# TM4C129ENCPDT register map
File version: 1.0
CPU: CORTEX_M4 1.0, other endian, MPU, FPU, 3 interrupt priority bits
Registers are 32-bit, read-write, reset 0x0 unless marked. A register's access mark holds for its fields unless they carry their own. Offsets are from the block's base; [hi:lo] are bit positions; {n}, {i} and the like mark numbered series.

## ADC0 — ADC register offsets
Base 0x40038000
Same registers: ADC1 0x40039000
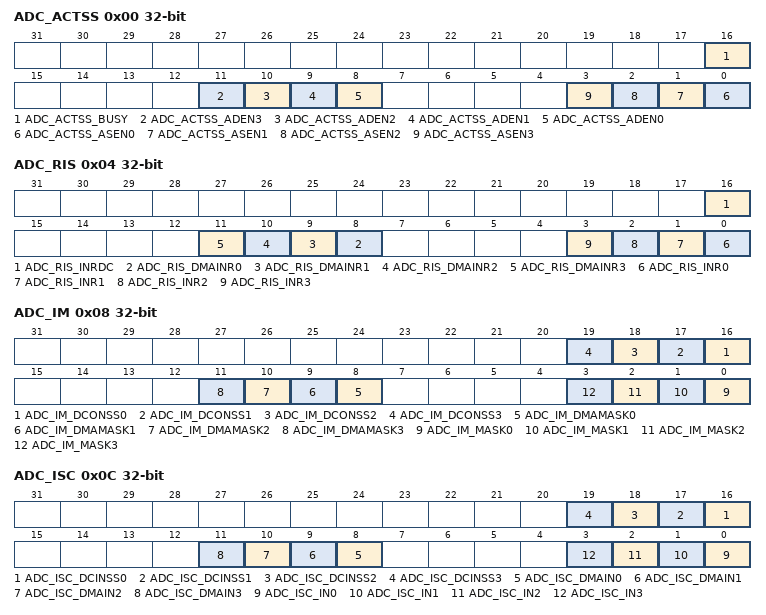
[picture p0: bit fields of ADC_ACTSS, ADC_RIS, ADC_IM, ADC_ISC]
0x00 ADC_ACTSS — ADC Active Sample Sequencer
  [16] ADC_ACTSS_BUSY — [16:16] ADC Busy
  [11] ADC_ACTSS_ADEN3 — [11:11] ADC SS3 DMA Enable
  [10] ADC_ACTSS_ADEN2 — [10:10] ADC SS2 DMA Enable
  [9] ADC_ACTSS_ADEN1 — [9:9] ADC SS1 DMA Enable
  [8] ADC_ACTSS_ADEN0 — [8:8] ADC SS1 DMA Enable
  [n] ADC_ACTSS_ASEN{n} (n=0..3) — [{n}:{n}] ADC SS{n} Enable
0x04 ADC_RIS — ADC Raw Interrupt Status
  [16] ADC_RIS_INRDC — [16:16] Digital Comparator Raw Interrupt Status
  [n+8] ADC_RIS_DMAINR{n} (n=0..3) — [{n+8}:{n+8}] SS{n} DMA Raw Interrupt Status
  [n] ADC_RIS_INR{n} (n=0..3) — [{n}:{n}] SS{n} Raw Interrupt Status
0x08 ADC_IM — ADC Interrupt Mask
  [n+16] ADC_IM_DCONSS{n} (n=0..3) — [{n+16}:{n+16}] Digital Comparator Interrupt on SS{n}
  [n+8] ADC_IM_DMAMASK{n} (n=0..3) — [{n+8}:{n+8}] SS{n} DMA Interrupt Mask
  [n] ADC_IM_MASK{n} (n=0..3) — [{n}:{n}] SS{n} Interrupt Mask
0x0C ADC_ISC — ADC Interrupt Status and Clear
  [n+16] ADC_ISC_DCINSS{n} (n=0..3) — [{n+16}:{n+16}] Digital Comparator Interrupt Status on SS{n}
  [n+8] ADC_ISC_DMAIN{n} (n=0..3) — [{n+8}:{n+8}] SS{n} DMA Interrupt Status and Clear
  [n] ADC_ISC_IN{n} (n=0..3) — [{n}:{n}] SS{n} Interrupt Status and Clear
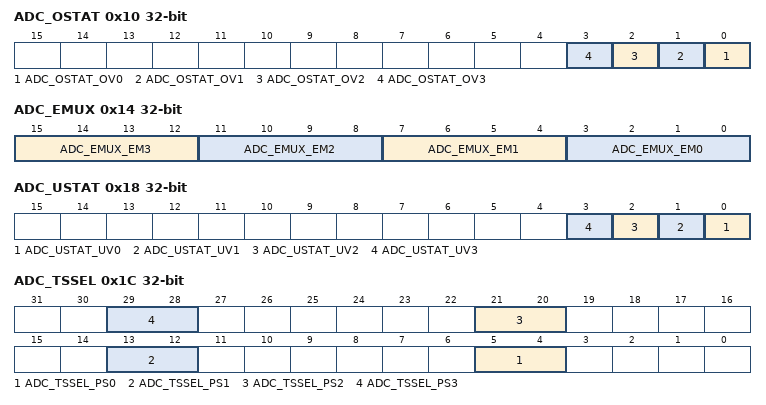
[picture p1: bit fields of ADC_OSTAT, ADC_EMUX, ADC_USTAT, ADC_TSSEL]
0x10 ADC_OSTAT — ADC Overflow Status
  [n] ADC_OSTAT_OV{n} (n=0..3) — [{n}:{n}] SS{n} FIFO Overflow
0x14 ADC_EMUX — ADC Event Multiplexer Select
  [15:12] ADC_EMUX_EM3 — [15:12] SS3 Trigger Select
    0=ADC_EMUX_EM3_PROCESSOR (Processor (default)); 0x1000=ADC_EMUX_EM3_COMP0 (Analog Comparator 0); 0x2000=ADC_EMUX_EM3_COMP1 (Analog Comparator 1); 0x3000=ADC_EMUX_EM3_COMP2 (Analog Comparator 2); 0x4000=ADC_EMUX_EM3_EXTERNAL (External (GPIO Pins)); 0x5000=ADC_EMUX_EM3_TIMER (Timer); 0x6000=ADC_EMUX_EM3_PWM0 (PWM generator 0); 0x7000=ADC_EMUX_EM3_PWM1 (PWM generator 1); 0x8000=ADC_EMUX_EM3_PWM2 (PWM generator 2); 0x9000=ADC_EMUX_EM3_PWM3 (PWM generator 3); 0xE000=ADC_EMUX_EM3_NEVER (Never Trigger); 0xF000=ADC_EMUX_EM3_ALWAYS (Always (continuously sample))
  [11:8] ADC_EMUX_EM2 — [11:8] SS2 Trigger Select
    0=ADC_EMUX_EM2_PROCESSOR (Processor (default)); 0x100=ADC_EMUX_EM2_COMP0 (Analog Comparator 0); 0x200=ADC_EMUX_EM2_COMP1 (Analog Comparator 1); 0x300=ADC_EMUX_EM2_COMP2 (Analog Comparator 2); 0x400=ADC_EMUX_EM2_EXTERNAL (External (GPIO Pins)); 0x500=ADC_EMUX_EM2_TIMER (Timer); 0x600=ADC_EMUX_EM2_PWM0 (PWM generator 0); 0x700=ADC_EMUX_EM2_PWM1 (PWM generator 1); 0x800=ADC_EMUX_EM2_PWM2 (PWM generator 2); 0x900=ADC_EMUX_EM2_PWM3 (PWM generator 3); 0xE00=ADC_EMUX_EM2_NEVER (Never Trigger); 0xF00=ADC_EMUX_EM2_ALWAYS (Always (continuously sample))
  [7:4] ADC_EMUX_EM1 — [7:4] SS1 Trigger Select
    0=ADC_EMUX_EM1_PROCESSOR (Processor (default)); 16=ADC_EMUX_EM1_COMP0 (Analog Comparator 0); 32=ADC_EMUX_EM1_COMP1 (Analog Comparator 1); 48=ADC_EMUX_EM1_COMP2 (Analog Comparator 2); 64=ADC_EMUX_EM1_EXTERNAL (External (GPIO Pins)); 80=ADC_EMUX_EM1_TIMER (Timer); 96=ADC_EMUX_EM1_PWM0 (PWM generator 0); 112=ADC_EMUX_EM1_PWM1 (PWM generator 1); 128=ADC_EMUX_EM1_PWM2 (PWM generator 2); 144=ADC_EMUX_EM1_PWM3 (PWM generator 3); 224=ADC_EMUX_EM1_NEVER (Never Trigger); 240=ADC_EMUX_EM1_ALWAYS (Always (continuously sample))
  [3:0] ADC_EMUX_EM0 — [3:0] SS0 Trigger Select
    0=ADC_EMUX_EM0_PROCESSOR (Processor (default)); 1=ADC_EMUX_EM0_COMP0 (Analog Comparator 0); 2=ADC_EMUX_EM0_COMP1 (Analog Comparator 1); 3=ADC_EMUX_EM0_COMP2 (Analog Comparator 2); 4=ADC_EMUX_EM0_EXTERNAL (External (GPIO Pins)); 5=ADC_EMUX_EM0_TIMER (Timer); {v}=ADC_EMUX_EM0_PWM{v-6} (PWM generator {v-6}) (v=6..9); 14=ADC_EMUX_EM0_NEVER (Never Trigger); 15=ADC_EMUX_EM0_ALWAYS (Always (continuously sample))
0x18 ADC_USTAT — ADC Underflow Status
  [n] ADC_USTAT_UV{n} (n=0..3) — [{n}:{n}] SS{n} FIFO Underflow
0x1C ADC_TSSEL — ADC Trigger Source Select
  [8n+5:8n+4] ADC_TSSEL_PS{n} (n=0..3) — [{8n+5}:{8n+4}] Generator {n} PWM Module Trigger Select
    0=Use Generator {n} (and its trigger) in PWM module 0
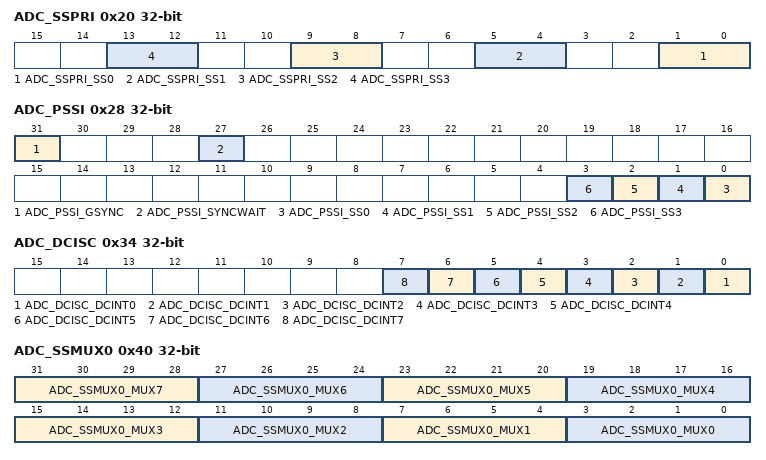
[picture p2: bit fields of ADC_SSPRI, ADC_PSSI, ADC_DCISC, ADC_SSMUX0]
0x20 ADC_SSPRI — ADC Sample Sequencer Priority
  [4n+1:4n] ADC_SSPRI_SS{n} (n=0..3) — [{4n+1}:{4n}] SS{n} Priority
0x24 ADC_SPC — ADC Sample Phase Control
  [3:0] ADC_SPC_PHASE — [3:0] Phase Difference
    0=ADC sample lags by 0.0; 1=ADC_SPC_PHASE_22_5 (ADC sample lags by 22.5); 2=ADC sample lags by 45.0; 3=ADC_SPC_PHASE_67_5 (ADC sample lags by 67.5); 4=ADC sample lags by 90.0; 5=ADC_SPC_PHASE_112_5 (ADC sample lags by 112.5); 6=ADC sample lags by 135.0; 7=ADC_SPC_PHASE_157_5 (ADC sample lags by 157.5); 8=ADC sample lags by 180.0; 9=ADC_SPC_PHASE_202_5 (ADC sample lags by 202.5); 10=ADC sample lags by 225.0; 11=ADC_SPC_PHASE_247_5 (ADC sample lags by 247.5); 12=ADC sample lags by 270.0; 13=ADC_SPC_PHASE_292_5 (ADC sample lags by 292.5); 14=ADC sample lags by 315.0; 15=ADC_SPC_PHASE_337_5 (ADC sample lags by 337.5)
0x28 ADC_PSSI — ADC Processor Sample Sequence Initiate
  [31] ADC_PSSI_GSYNC — [31:31] Global Synchronize
  [27] ADC_PSSI_SYNCWAIT — [27:27] Synchronize Wait
  [n] ADC_PSSI_SS{n} (n=0..3) — [{n}:{n}] SS{n} Initiate
0x30 ADC_SAC — ADC Sample Averaging Control
  [2:0] ADC_SAC_AVG — [2:0] Hardware Averaging Control
    0=ADC_SAC_AVG_OFF (No hardware oversampling); 1=ADC_SAC_AVG_2X (2x hardware oversampling); 2=ADC_SAC_AVG_4X (4x hardware oversampling); 3=ADC_SAC_AVG_8X (8x hardware oversampling); 4=ADC_SAC_AVG_16X (16x hardware oversampling); 5=ADC_SAC_AVG_32X (32x hardware oversampling); 6=ADC_SAC_AVG_64X (64x hardware oversampling)
0x34 ADC_DCISC — ADC Digital Comparator Interrupt Status and Clear
  [n] ADC_DCISC_DCINT{n} (n=0..7) — [{n}:{n}] Digital Comparator {n} Interrupt Status and Clear
0x38 ADC_CTL — ADC Control
  [0] ADC_CTL_VREF — [0:0] Voltage Reference Select
    0=ADC_CTL_VREF_INTERNAL (VDDA and GNDA are the voltage references); 1=ADC_CTL_VREF_EXT_3V (The external VREFA+ and VREFA- inputs are the voltage references)
0x40 ADC_SSMUX0 — ADC Sample Sequence Input Multiplexer Select 0
  [4n+3:4n] ADC_SSMUX0_MUX{n} (n=3..7) — [{4n+3}:{4n}] {n+1}th Sample Input Select
  [11:8] ADC_SSMUX0_MUX2 — [11:8] 3rd Sample Input Select
  [7:4] ADC_SSMUX0_MUX1 — [7:4] 2nd Sample Input Select
  [3:0] ADC_SSMUX0_MUX0 — [3:0] 1st Sample Input Select
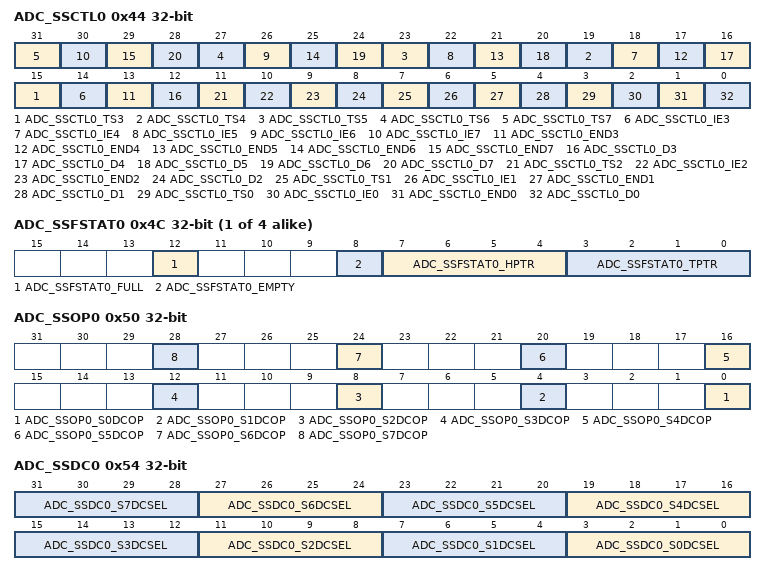
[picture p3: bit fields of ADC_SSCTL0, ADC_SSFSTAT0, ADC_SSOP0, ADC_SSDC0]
0x44 ADC_SSCTL0 — ADC Sample Sequence Control 0
  [4n+3] ADC_SSCTL0_TS{n} (n=3..7) — [{4n+3}:{4n+3}] {n+1}th Sample Temp Sensor Select
  [4n+2] ADC_SSCTL0_IE{n} (n=3..7) — [{4n+2}:{4n+2}] {n+1}th Sample Interrupt Enable
  [4n+1] ADC_SSCTL0_END{n} (n=3..7) — [{4n+1}:{4n+1}] {n+1}th Sample is End of Sequence
  [4n] ADC_SSCTL0_D{n} (n=3..7) — [{4n}:{4n}] {n+1}th Sample Differential Input Select
  [11] ADC_SSCTL0_TS2 — [11:11] 3rd Sample Temp Sensor Select
  [10] ADC_SSCTL0_IE2 — [10:10] 3rd Sample Interrupt Enable
  [9] ADC_SSCTL0_END2 — [9:9] 3rd Sample is End of Sequence
  [8] ADC_SSCTL0_D2 — [8:8] 3rd Sample Differential Input Select
  [7] ADC_SSCTL0_TS1 — [7:7] 2nd Sample Temp Sensor Select
  [6] ADC_SSCTL0_IE1 — [6:6] 2nd Sample Interrupt Enable
  [5] ADC_SSCTL0_END1 — [5:5] 2nd Sample is End of Sequence
  [4] ADC_SSCTL0_D1 — [4:4] 2nd Sample Differential Input Select
  [3] ADC_SSCTL0_TS0 — [3:3] 1st Sample Temp Sensor Select
  [2] ADC_SSCTL0_IE0 — [2:2] 1st Sample Interrupt Enable
  [1] ADC_SSCTL0_END0 — [1:1] 1st Sample is End of Sequence
  [0] ADC_SSCTL0_D0 — [0:0] 1st Sample Differential Input Select
{0x48+0x20*i} ADC_SSFIFO{i} (i=0..3) — ADC Sample Sequence Result FIFO {i}
  [11:0] ADC_SSFIFO{i}_DATA — [11:0] Conversion Result Data
{0x4C+0x20*i} ADC_SSFSTAT{i} (i=0..3) — ADC Sample Sequence FIFO {i} Status
  [12] ADC_SSFSTAT{i}_FULL — [12:12] FIFO Full
  [8] ADC_SSFSTAT{i}_EMPTY — [8:8] FIFO Empty
  [7:4] ADC_SSFSTAT{i}_HPTR — [7:4] FIFO Head Pointer
  [3:0] ADC_SSFSTAT{i}_TPTR — [3:0] FIFO Tail Pointer
0x50 ADC_SSOP0 — ADC Sample Sequence 0 Operation
  [4n] ADC_SSOP0_S{n}DCOP (n=0..7) — [{4n}:{4n}] Sample {n} Digital Comparator Operation
0x54 ADC_SSDC0 — ADC Sample Sequence 0 Digital Comparator Select
  [4n+3:4n] ADC_SSDC0_S{n}DCSEL (n=0..7) — [{4n+3}:{4n}] Sample {n} Digital Comparator Select
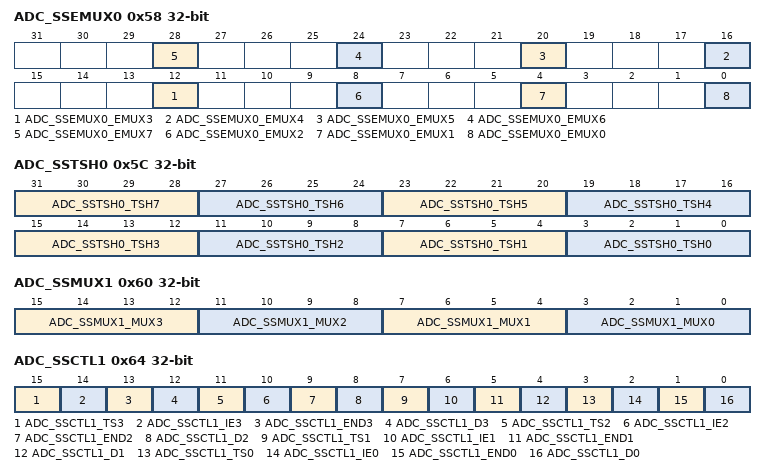
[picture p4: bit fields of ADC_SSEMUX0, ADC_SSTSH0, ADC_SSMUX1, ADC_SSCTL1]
0x58 ADC_SSEMUX0 — ADC Sample Sequence Extended Input Multiplexer Select 0
  [4n] ADC_SSEMUX0_EMUX{n} (n=3..7) — [{4n}:{4n}] {n+1}th Sample Input Select (Upper Bit)
  [8] ADC_SSEMUX0_EMUX2 — [8:8] 3rd Sample Input Select (Upper Bit)
  [4] ADC_SSEMUX0_EMUX1 — [4:4] 2th Sample Input Select (Upper Bit)
  [0] ADC_SSEMUX0_EMUX0 — [0:0] 1st Sample Input Select (Upper Bit)
0x5C ADC_SSTSH0 — ADC Sample Sequence 0 Sample and Hold Time
  [4n+3:4n] ADC_SSTSH0_TSH{n} (n=3..7) — [{4n+3}:{4n}] {n+1}th Sample and Hold Period Select
  [11:8] ADC_SSTSH0_TSH2 — [11:8] 3rd Sample and Hold Period Select
  [7:4] ADC_SSTSH0_TSH1 — [7:4] 2nd Sample and Hold Period Select
  [3:0] ADC_SSTSH0_TSH0 — [3:0] 1st Sample and Hold Period Select
0x60 ADC_SSMUX1 — ADC Sample Sequence Input Multiplexer Select 1
  [15:12] ADC_SSMUX1_MUX3 — [15:12] 4th Sample Input Select
  [11:8] ADC_SSMUX1_MUX2 — [11:8] 3rd Sample Input Select
  [7:4] ADC_SSMUX1_MUX1 — [7:4] 2nd Sample Input Select
  [3:0] ADC_SSMUX1_MUX0 — [3:0] 1st Sample Input Select
0x64 ADC_SSCTL1 — ADC Sample Sequence Control 1
  [15] ADC_SSCTL1_TS3 — [15:15] 4th Sample Temp Sensor Select
  [14] ADC_SSCTL1_IE3 — [14:14] 4th Sample Interrupt Enable
  [13] ADC_SSCTL1_END3 — [13:13] 4th Sample is End of Sequence
  [12] ADC_SSCTL1_D3 — [12:12] 4th Sample Differential Input Select
  [11] ADC_SSCTL1_TS2 — [11:11] 3rd Sample Temp Sensor Select
  [10] ADC_SSCTL1_IE2 — [10:10] 3rd Sample Interrupt Enable
  [9] ADC_SSCTL1_END2 — [9:9] 3rd Sample is End of Sequence
  [8] ADC_SSCTL1_D2 — [8:8] 3rd Sample Differential Input Select
  [7] ADC_SSCTL1_TS1 — [7:7] 2nd Sample Temp Sensor Select
  [6] ADC_SSCTL1_IE1 — [6:6] 2nd Sample Interrupt Enable
  [5] ADC_SSCTL1_END1 — [5:5] 2nd Sample is End of Sequence
  [4] ADC_SSCTL1_D1 — [4:4] 2nd Sample Differential Input Select
  [3] ADC_SSCTL1_TS0 — [3:3] 1st Sample Temp Sensor Select
  [2] ADC_SSCTL1_IE0 — [2:2] 1st Sample Interrupt Enable
  [1] ADC_SSCTL1_END0 — [1:1] 1st Sample is End of Sequence
  [0] ADC_SSCTL1_D0 — [0:0] 1st Sample Differential Input Select
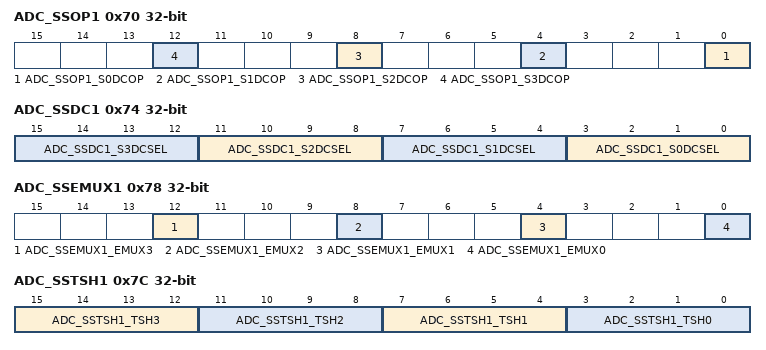
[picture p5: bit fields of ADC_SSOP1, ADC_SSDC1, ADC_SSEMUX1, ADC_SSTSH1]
0x70 ADC_SSOP1 — ADC Sample Sequence 1 Operation
  [4n] ADC_SSOP1_S{n}DCOP (n=0..3) — [{4n}:{4n}] Sample {n} Digital Comparator Operation
0x74 ADC_SSDC1 — ADC Sample Sequence 1 Digital Comparator Select
  [4n+3:4n] ADC_SSDC1_S{n}DCSEL (n=0..3) — [{4n+3}:{4n}] Sample {n} Digital Comparator Select
0x78 ADC_SSEMUX1 — ADC Sample Sequence Extended Input Multiplexer Select 1
  [12] ADC_SSEMUX1_EMUX3 — [12:12] 4th Sample Input Select (Upper Bit)
  [8] ADC_SSEMUX1_EMUX2 — [8:8] 3rd Sample Input Select (Upper Bit)
  [4] ADC_SSEMUX1_EMUX1 — [4:4] 2th Sample Input Select (Upper Bit)
  [0] ADC_SSEMUX1_EMUX0 — [0:0] 1st Sample Input Select (Upper Bit)
0x7C ADC_SSTSH1 — ADC Sample Sequence 1 Sample and Hold Time
  [15:12] ADC_SSTSH1_TSH3 — [15:12] 4th Sample and Hold Period Select
  [11:8] ADC_SSTSH1_TSH2 — [11:8] 3rd Sample and Hold Period Select
  [7:4] ADC_SSTSH1_TSH1 — [7:4] 2nd Sample and Hold Period Select
  [3:0] ADC_SSTSH1_TSH0 — [3:0] 1st Sample and Hold Period Select
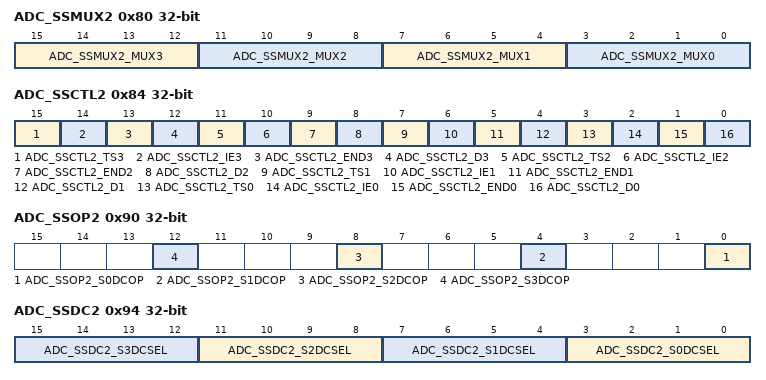
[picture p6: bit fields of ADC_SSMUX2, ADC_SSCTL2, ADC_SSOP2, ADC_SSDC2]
0x80 ADC_SSMUX2 — ADC Sample Sequence Input Multiplexer Select 2
  [15:12] ADC_SSMUX2_MUX3 — [15:12] 4th Sample Input Select
  [11:8] ADC_SSMUX2_MUX2 — [11:8] 3rd Sample Input Select
  [7:4] ADC_SSMUX2_MUX1 — [7:4] 2nd Sample Input Select
  [3:0] ADC_SSMUX2_MUX0 — [3:0] 1st Sample Input Select
0x84 ADC_SSCTL2 — ADC Sample Sequence Control 2
  [15] ADC_SSCTL2_TS3 — [15:15] 4th Sample Temp Sensor Select
  [14] ADC_SSCTL2_IE3 — [14:14] 4th Sample Interrupt Enable
  [13] ADC_SSCTL2_END3 — [13:13] 4th Sample is End of Sequence
  [12] ADC_SSCTL2_D3 — [12:12] 4th Sample Differential Input Select
  [11] ADC_SSCTL2_TS2 — [11:11] 3rd Sample Temp Sensor Select
  [10] ADC_SSCTL2_IE2 — [10:10] 3rd Sample Interrupt Enable
  [9] ADC_SSCTL2_END2 — [9:9] 3rd Sample is End of Sequence
  [8] ADC_SSCTL2_D2 — [8:8] 3rd Sample Differential Input Select
  [7] ADC_SSCTL2_TS1 — [7:7] 2nd Sample Temp Sensor Select
  [6] ADC_SSCTL2_IE1 — [6:6] 2nd Sample Interrupt Enable
  [5] ADC_SSCTL2_END1 — [5:5] 2nd Sample is End of Sequence
  [4] ADC_SSCTL2_D1 — [4:4] 2nd Sample Differential Input Select
  [3] ADC_SSCTL2_TS0 — [3:3] 1st Sample Temp Sensor Select
  [2] ADC_SSCTL2_IE0 — [2:2] 1st Sample Interrupt Enable
  [1] ADC_SSCTL2_END0 — [1:1] 1st Sample is End of Sequence
  [0] ADC_SSCTL2_D0 — [0:0] 1st Sample Differential Input Select
0x90 ADC_SSOP2 — ADC Sample Sequence 2 Operation
  [4n] ADC_SSOP2_S{n}DCOP (n=0..3) — [{4n}:{4n}] Sample {n} Digital Comparator Operation
0x94 ADC_SSDC2 — ADC Sample Sequence 2 Digital Comparator Select
  [4n+3:4n] ADC_SSDC2_S{n}DCSEL (n=0..3) — [{4n+3}:{4n}] Sample {n} Digital Comparator Select
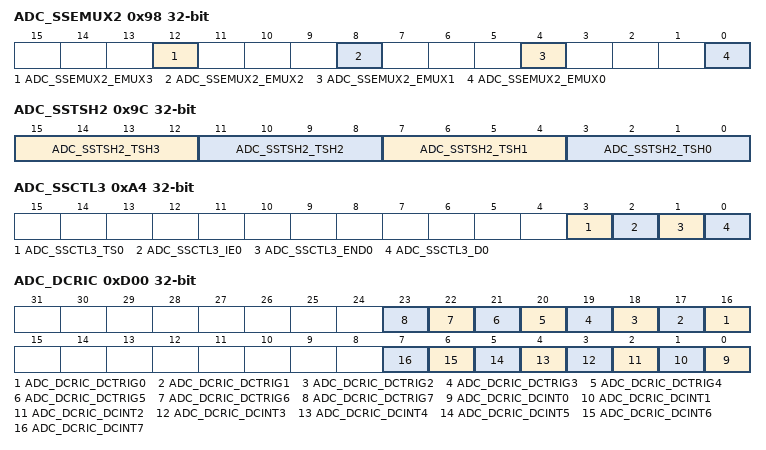
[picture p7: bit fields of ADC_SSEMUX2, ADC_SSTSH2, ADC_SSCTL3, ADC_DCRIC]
0x98 ADC_SSEMUX2 — ADC Sample Sequence Extended Input Multiplexer Select 2
  [12] ADC_SSEMUX2_EMUX3 — [12:12] 4th Sample Input Select (Upper Bit)
  [8] ADC_SSEMUX2_EMUX2 — [8:8] 3rd Sample Input Select (Upper Bit)
  [4] ADC_SSEMUX2_EMUX1 — [4:4] 2th Sample Input Select (Upper Bit)
  [0] ADC_SSEMUX2_EMUX0 — [0:0] 1st Sample Input Select (Upper Bit)
0x9C ADC_SSTSH2 — ADC Sample Sequence 2 Sample and Hold Time
  [15:12] ADC_SSTSH2_TSH3 — [15:12] 4th Sample and Hold Period Select
  [11:8] ADC_SSTSH2_TSH2 — [11:8] 3rd Sample and Hold Period Select
  [7:4] ADC_SSTSH2_TSH1 — [7:4] 2nd Sample and Hold Period Select
  [3:0] ADC_SSTSH2_TSH0 — [3:0] 1st Sample and Hold Period Select
0xA0 ADC_SSMUX3 — ADC Sample Sequence Input Multiplexer Select 3
  [3:0] ADC_SSMUX3_MUX0 — [3:0] 1st Sample Input Select
0xA4 ADC_SSCTL3 — ADC Sample Sequence Control 3
  [3] ADC_SSCTL3_TS0 — [3:3] 1st Sample Temp Sensor Select
  [2] ADC_SSCTL3_IE0 — [2:2] Sample Interrupt Enable
  [1] ADC_SSCTL3_END0 — [1:1] End of Sequence
  [0] ADC_SSCTL3_D0 — [0:0] Sample Differential Input Select
0xB0 ADC_SSOP3 — ADC Sample Sequence 3 Operation
  [0] ADC_SSOP3_S0DCOP — [0:0] Sample 0 Digital Comparator Operation
0xB4 ADC_SSDC3 — ADC Sample Sequence 3 Digital Comparator Select
  [3:0] ADC_SSDC3_S0DCSEL — [3:0] Sample 0 Digital Comparator Select
0xB8 ADC_SSEMUX3 — ADC Sample Sequence Extended Input Multiplexer Select 3
  [0] ADC_SSEMUX3_EMUX0 — [0:0] 1st Sample Input Select (Upper Bit)
0xBC ADC_SSTSH3 — ADC Sample Sequence 3 Sample and Hold Time
  [3:0] ADC_SSTSH3_TSH0 — [3:0] 1st Sample and Hold Period Select
0xD00 ADC_DCRIC — ADC Digital Comparator Reset Initial Conditions
  [n+16] ADC_DCRIC_DCTRIG{n} (n=0..7) — [{n+16}:{n+16}] Digital Comparator Trigger {n}
  [n] ADC_DCRIC_DCINT{n} (n=0..7) — [{n}:{n}] Digital Comparator Interrupt {n}
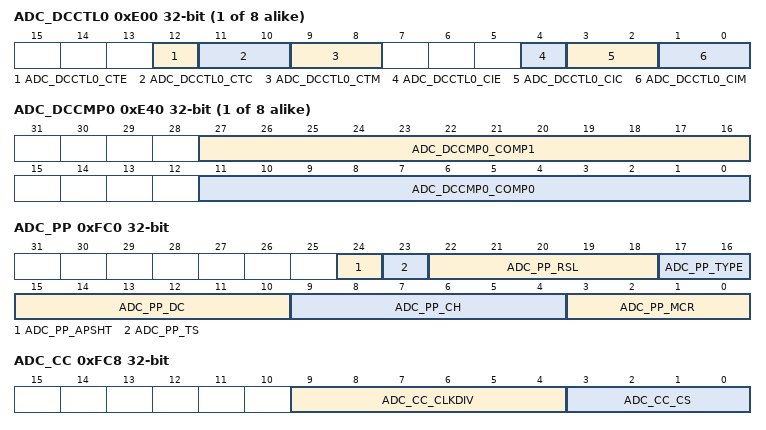
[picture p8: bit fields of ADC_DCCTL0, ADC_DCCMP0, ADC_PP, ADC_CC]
{0xE00+4i} ADC_DCCTL{i} (i=0..7) — ADC Digital Comparator Control {i}
  [12] ADC_DCCTL{i}_CTE — [12:12] Comparison Trigger Enable
  [11:10] ADC_DCCTL{i}_CTC — [11:10] Comparison Trigger Condition
    0=ADC_DCCTL{i}_CTC_LOW (Low Band); 0x400=ADC_DCCTL{i}_CTC_MID (Mid Band); 0xC00=ADC_DCCTL{i}_CTC_HIGH (High Band)
  [9:8] ADC_DCCTL{i}_CTM — [9:8] Comparison Trigger Mode
    0=ADC_DCCTL{i}_CTM_ALWAYS (Always); 0x100=ADC_DCCTL{i}_CTM_ONCE (Once); 0x200=ADC_DCCTL{i}_CTM_HALWAYS (Hysteresis Always); 0x300=ADC_DCCTL{i}_CTM_HONCE (Hysteresis Once)
  [4] ADC_DCCTL{i}_CIE — [4:4] Comparison Interrupt Enable
  [3:2] ADC_DCCTL{i}_CIC — [3:2] Comparison Interrupt Condition
    0=ADC_DCCTL{i}_CIC_LOW (Low Band); 4=ADC_DCCTL{i}_CIC_MID (Mid Band); 12=ADC_DCCTL{i}_CIC_HIGH (High Band)
  [1:0] ADC_DCCTL{i}_CIM — [1:0] Comparison Interrupt Mode
    0=ADC_DCCTL{i}_CIM_ALWAYS (Always); 1=ADC_DCCTL{i}_CIM_ONCE (Once); 2=ADC_DCCTL{i}_CIM_HALWAYS (Hysteresis Always); 3=ADC_DCCTL{i}_CIM_HONCE (Hysteresis Once)
{0xE40+4i} ADC_DCCMP{i} (i=0..7) — ADC Digital Comparator Range {i}
  [27:16] ADC_DCCMP{i}_COMP1 — [27:16] Compare 1
  [11:0] ADC_DCCMP{i}_COMP0 — [11:0] Compare 0
0xFC0 ADC_PP — ADC Peripheral Properties
  [24] ADC_PP_APSHT — [24:24] Application-Programmable Sample-and-Hold Time
  [23] ADC_PP_TS — [23:23] Temperature Sensor
  [22:18] ADC_PP_RSL — [22:18] Resolution
  [17:16] ADC_PP_TYPE — [17:16] ADC Architecture
    0=ADC_PP_TYPE_SAR (SAR)
  [15:10] ADC_PP_DC — [15:10] Digital Comparator Count
  [9:4] ADC_PP_CH — [9:4] ADC Channel Count
  [3:0] ADC_PP_MCR — [3:0] Maximum Conversion Rate
    7=ADC_PP_MCR_FULL (Full conversion rate (FCONV) as defined by TADC and NSH)
0xFC4 ADC_PC — ADC Peripheral Configuration
  [3:0] ADC_PC_MCR — [3:0] Conversion Rate
    1=ADC_PC_MCR_1_8 (Eighth conversion rate. After a conversion completes, the logic pauses for 112 TADC periods before starting the next conversion); 3=ADC_PC_MCR_1_4 (Quarter conversion rate. After a conversion completes, the logic pauses for 48 TADC periods before starting the next conversion); 5=ADC_PC_MCR_1_2 (Half conversion rate. After a conversion completes, the logic pauses for 16 TADC periods before starting the next conversion); 7=ADC_PC_MCR_FULL (Full conversion rate (FCONV) as defined by TADC and NSH)
0xFC8 ADC_CC — ADC Clock Configuration
  [9:4] ADC_CC_CLKDIV — [9:4] PLL VCO Clock Divisor
  [3:0] ADC_CC_CS — [3:0] ADC Clock Source
    0=ADC_CC_CS_SYSPLL (PLL VCO divided by CLKDIV); 1=ADC_CC_CS_PIOSC (PIOSC); 2=ADC_CC_CS_MOSC (MOSC)
